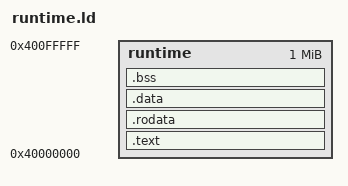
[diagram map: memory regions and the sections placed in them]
INCLUDE generated/output_format.ld
ENTRY(_start)

INCLUDE generated/regions.ld

MEMORY {
	runtime : ORIGIN = 0x40000000, LENGTH = 0x100000 /* 1M */
}

PROVIDE(_fstack = 0x40000000 + 0x200000 - 4);

SECTIONS
{
	.text :
	{
		_ftext = .;
		*(.text .stub .text.* .gnu.linkonce.t.*)
		_etext = .;
	} > runtime

	.rodata :
	{
		. = ALIGN(4);
		_frodata = .;
		*(.rodata .rodata.* .gnu.linkonce.r.*)
		*(.rodata1)
		_erodata = .;
	} > runtime

	.data :
	{
		. = ALIGN(4);
		_fdata = .;
		*(.data .data.* .gnu.linkonce.d.*)
		*(.data1)
		*(.sdata .sdata.* .gnu.linkonce.s.*)
		_edata = .;
	} > runtime

	.bss :
	{
		. = ALIGN(4);
		_fbss = .;
		*(.dynsbss)
		*(.sbss .sbss.* .gnu.linkonce.sb.*)
		*(.scommon)
		*(.dynbss)
		*(.bss .bss.* .gnu.linkonce.b.*)
		*(COMMON)
		. = ALIGN(4);
		_ebss = .;
		. = ALIGN(8);
	} > runtime

	/DISCARD/ :
	{
		*(.eh_frame)
	}
}
